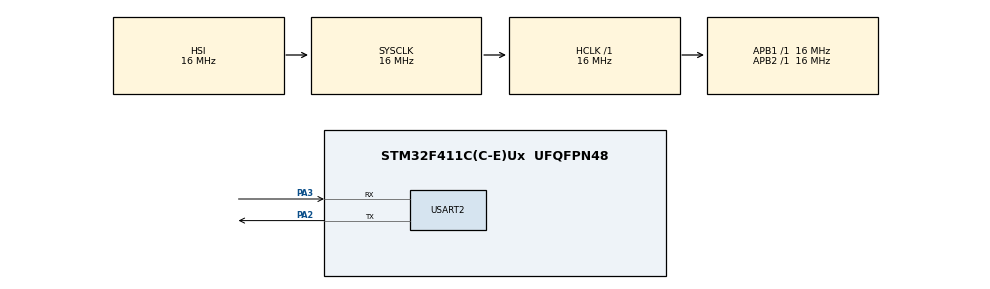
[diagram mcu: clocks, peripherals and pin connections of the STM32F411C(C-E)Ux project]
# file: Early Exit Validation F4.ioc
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Mcu.Family=STM32F4
Mcu.Name=STM32F411C(C-E)Ux
Mcu.Package=UFQFPN48
NVIC.PriorityGroup=NVIC_PRIORITYGROUP_4
PA13.Mode=Serial_Wire
PA13.Signal=SYS_JTMS-SWDIO
PA14.Mode=Serial_Wire
PA14.Signal=SYS_JTCK-SWCLK
PA2.Mode=Asynchronous
PA2.Signal=USART2_TX
PA3.Mode=Asynchronous
PA3.Signal=USART2_RX
ProjectManager.HeapSize=0x200
ProjectManager.StackSize=0x400
ProjectManager.TargetToolchain=STM32CubeIDE
RCC.AHBFreq_Value=16000000
RCC.APB1Freq_Value=16000000
RCC.APB2Freq_Value=16000000
RCC.CortexFreq_Value=16000000
RCC.HSE_VALUE=25000000
RCC.HSI_VALUE=16000000
RCC.LSE_VALUE=32768
RCC.SYSCLKFreq_VALUE=16000000
RCC.VCOOutputFreq_Value=192000000
STMicroelectronics.X-CUBE-AI.10.2.0.ActivationBufferSizeList=44732,44808,33208
STMicroelectronics.X-CUBE-AI.10.2.0.ActivationBuffers=pool0;pool0;pool0
STMicroelectronics.X-CUBE-AI.10.2.0.ActivationNames=pool0
STMicroelectronics.X-CUBE-AI.10.2.0.ActivationSizes=AI_NETWORK_1_DATA_ACTIVATION_1_SIZE
STMicroelectronics.X-CUBE-AI.10.2.0.ApplicationCcDeviceJjApplication=ApplicationTemplate
STMicroelectronics.X-CUBE-AI.10.2.0.HeapSize=0x800
STMicroelectronics.X-CUBE-AI.10.2.0.InternalRamActivationBufferMaxSize=AI_NETWORK_2_DATA_ACTIVATIONS_SIZE
STMicroelectronics.X-CUBE-AI.10.2.0.LatestDirectoryUsed-30e20236ca451895675bc07523db207a53c078bcb4689693956d8f04bd235fb7=D\:\\ARM Hackathon\\FINAL_HANDOFF
STMicroelectronics.X-CUBE-AI.10.2.0.LatestDirectoryUsed-bb43a51bcba1cfc3cbbd9259078b81ac906280b69a4e43d4efa3b40d29e1984f=D\:\\ARM Hackathon\\FINAL_HANDOFF
STMicroelectronics.X-CUBE-AI.10.2.0.LatestDirectoryUsed-d4300d666fe291a5c7089841f6ab343c647e5c0c7583c0506bb5bf4ecedfb07b=D\:\\ARM Hackathon\\FINAL_HANDOFF
STMicroelectronics.X-CUBE-AI.10.2.0.MaximumNumberOfInputLayer=1
STMicroelectronics.X-CUBE-AI.10.2.0.MaximumNumberOfOutputLayer=1
STMicroelectronics.X-CUBE-AI.10.2.0.MaximumSizeOfInputLayer=1
STMicroelectronics.X-CUBE-AI.10.2.0.MaximumSizeOfOutputLayer=1
STMicroelectronics.X-CUBE-AI.10.2.0.ModelActualCompression-30e20236ca451895675bc07523db207a53c078bcb4689693956d8f04bd235fb7=0.0
STMicroelectronics.X-CUBE-AI.10.2.0.ModelActualCompression-bb43a51bcba1cfc3cbbd9259078b81ac906280b69a4e43d4efa3b40d29e1984f=0.0
STMicroelectronics.X-CUBE-AI.10.2.0.ModelActualCompression-d4300d666fe291a5c7089841f6ab343c647e5c0c7583c0506bb5bf4ecedfb07b=0.0
STMicroelectronics.X-CUBE-AI.10.2.0.ModelCompression-30e20236ca451895675bc07523db207a53c078bcb4689693956d8f04bd235fb7=None
STMicroelectronics.X-CUBE-AI.10.2.0.ModelCompression-bb43a51bcba1cfc3cbbd9259078b81ac906280b69a4e43d4efa3b40d29e1984f=None
STMicroelectronics.X-CUBE-AI.10.2.0.ModelCompression-d4300d666fe291a5c7089841f6ab343c647e5c0c7583c0506bb5bf4ecedfb07b=None
STMicroelectronics.X-CUBE-AI.10.2.0.ModelFlashOccupation-30e20236ca451895675bc07523db207a53c078bcb4689693956d8f04bd235fb7=58004
STMicroelectronics.X-CUBE-AI.10.2.0.ModelFlashOccupation-bb43a51bcba1cfc3cbbd9259078b81ac906280b69a4e43d4efa3b40d29e1984f=60780
STMicroelectronics.X-CUBE-AI.10.2.0.ModelFlashOccupation-d4300d666fe291a5c7089841f6ab343c647e5c0c7583c0506bb5bf4ecedfb07b=12888
STMicroelectronics.X-CUBE-AI.10.2.0.ModelHashList=bb43a51bcba1cfc3cbbd9259078b81ac906280b69a4e43d4efa3b40d29e1984f;30e20236ca451895675bc07523db207a53c078bcb4689693956d8f04bd235fb7;d4300d666fe291a5c7089841f6ab343c647e5c0c7583c0506bb5bf4ecedfb07b
STMicroelectronics.X-CUBE-AI.10.2.0.ModelKind-30e20236ca451895675bc07523db207a53c078bcb4689693956d8f04bd235fb7=TFLITE
STMicroelectronics.X-CUBE-AI.10.2.0.ModelKind-bb43a51bcba1cfc3cbbd9259078b81ac906280b69a4e43d4efa3b40d29e1984f=TFLITE
STMicroelectronics.X-CUBE-AI.10.2.0.ModelKind-d4300d666fe291a5c7089841f6ab343c647e5c0c7583c0506bb5bf4ecedfb07b=TFLITE
STMicroelectronics.X-CUBE-AI.10.2.0.ModelMacc-30e20236ca451895675bc07523db207a53c078bcb4689693956d8f04bd235fb7=1209216
STMicroelectronics.X-CUBE-AI.10.2.0.ModelMacc-bb43a51bcba1cfc3cbbd9259078b81ac906280b69a4e43d4efa3b40d29e1984f=1528320
STMicroelectronics.X-CUBE-AI.10.2.0.ModelMacc-d4300d666fe291a5c7089841f6ab343c647e5c0c7583c0506bb5bf4ecedfb07b=8960
STMicroelectronics.X-CUBE-AI.10.2.0.ModelName-30e20236ca451895675bc07523db207a53c078bcb4689693956d8f04bd235fb7=network_2
STMicroelectronics.X-CUBE-AI.10.2.0.ModelName-bb43a51bcba1cfc3cbbd9259078b81ac906280b69a4e43d4efa3b40d29e1984f=network_1
STMicroelectronics.X-CUBE-AI.10.2.0.ModelName-d4300d666fe291a5c7089841f6ab343c647e5c0c7583c0506bb5bf4ecedfb07b=network_ee
STMicroelectronics.X-CUBE-AI.10.2.0.ModelNameList=network_1,network_2,network_ee
STMicroelectronics.X-CUBE-AI.10.2.0.ModelRamOccupation-30e20236ca451895675bc07523db207a53c078bcb4689693956d8f04bd235fb7=44808
STMicroelectronics.X-CUBE-AI.10.2.0.ModelRamOccupation-bb43a51bcba1cfc3cbbd9259078b81ac906280b69a4e43d4efa3b40d29e1984f=44732
STMicroelectronics.X-CUBE-AI.10.2.0.ModelRamOccupation-d4300d666fe291a5c7089841f6ab343c647e5c0c7583c0506bb5bf4ecedfb07b=33208
STMicroelectronics.X-CUBE-AI.10.2.0.ModelStructureFile-30e20236ca451895675bc07523db207a53c078bcb4689693956d8f04bd235fb7=D\:\\ARM Hackathon\\FINAL_HANDOFF\\network2.tflite
STMicroelectronics.X-CUBE-AI.10.2.0.ModelStructureFile-bb43a51bcba1cfc3cbbd9259078b81ac906280b69a4e43d4efa3b40d29e1984f=D\:\\ARM Hackathon\\FINAL_HANDOFF\\network1.tflite
STMicroelectronics.X-CUBE-AI.10.2.0.ModelStructureFile-d4300d666fe291a5c7089841f6ab343c647e5c0c7583c0506bb5bf4ecedfb07b=D\:\\ARM Hackathon\\FINAL_HANDOFF\\ee1.tflite
STMicroelectronics.X-CUBE-AI.10.2.0.ModelType-30e20236ca451895675bc07523db207a53c078bcb4689693956d8f04bd235fb7=STM32Cube.AI MCU runtime
STMicroelectronics.X-CUBE-AI.10.2.0.ModelType-bb43a51bcba1cfc3cbbd9259078b81ac906280b69a4e43d4efa3b40d29e1984f=STM32Cube.AI MCU runtime
STMicroelectronics.X-CUBE-AI.10.2.0.ModelType-d4300d666fe291a5c7089841f6ab343c647e5c0c7583c0506bb5bf4ecedfb07b=STM32Cube.AI MCU runtime
STMicroelectronics.X-CUBE-AI.10.2.0.ReadyForCodeGeneration=true
STMicroelectronics.X-CUBE-AI.10.2.0.StackSize=0x800
STMicroelectronics.X-CUBE-AI.10.2.0.WorkingBufferStartAddrList=0xFFFFFFFF,0xFFFFFFFF,0xFFFFFFFF
STMicroelectronics.X-CUBE-AI.10.2.0.XAaCUBEAaAICcArtificialOoIntelligenceJjCore=true
STMicroelectronics.X-CUBE-AI.10.2.0.copyWeightToRam=false
STMicroelectronics.X-CUBE-AI.10.2.0.customLayerConfigEnabled=false
STMicroelectronics.X-CUBE-AI.10.2.0.noOnnxIoTranspose=false
STMicroelectronics.X-CUBE-AI.10.2.0.useInputAllocation=true
STMicroelectronics.X-CUBE-AI.10.2.0.useOutputAllocation=true
USART2.VirtualMode=VM_ASYNC
VP_STMicroelectronics.X-CUBE-AI_VS_ArtificialOoIntelligenceJjXAaCUBEAaAI_10.2.0.Mode=ArtificialOoIntelligenceJjXAaCUBEAaAI
VP_STMicroelectronics.X-CUBE-AI_VS_DeviceJjApplication_10.2.0.Mode=DeviceJjApplication
board=custom

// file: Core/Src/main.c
/* USER CODE BEGIN Header */
/**
  ******************************************************************************
  * @file           : main.c
  * @brief          : Main program body
  ******************************************************************************
  * @attention
  *
  * Copyright (c) 2026 STMicroelectronics.
  * All rights reserved.
  *
  * This software is licensed under terms that can be found in the LICENSE file
  * in the root directory of this software component.
  * If no LICENSE file comes with this software, it is provided AS-IS.
  *
  ******************************************************************************
  */
/* USER CODE END Header */
#include "main.h"
#include "usart.h"
#include "gpio.h"
#include "app_x-cube-ai.h"

void SystemClock_Config(void);

/* USER CODE BEGIN 0 */
int __io_putchar(int ch)
{
    HAL_UART_Transmit(&huart2, (uint8_t *)&ch, 1, HAL_MAX_DELAY);
    return ch;
}
/* USER CODE END 0 */

int main(void)
{

  /* MCU Configuration--------------------------------------------------------*/

  /* Reset of all peripherals, Initializes the Flash interface and the Systick. */
  HAL_Init();

  /* Configure the system clock */
  SystemClock_Config();

  /* Initialize all configured peripherals */
  MX_GPIO_Init();
  MX_USART2_UART_Init();
  MX_X_CUBE_AI_Init();
  /* USER CODE BEGIN 2 */
  MX_X_CUBE_AI_Process();
  /* USER CODE END 2 */

  /* Infinite loop */
  while (1)
  {

  }
}

void SystemClock_Config(void)
{
  RCC_OscInitTypeDef RCC_OscInitStruct = {0};
  RCC_ClkInitTypeDef RCC_ClkInitStruct = {0};

  /** Configure the main internal regulator output voltage
  */
  __HAL_RCC_PWR_CLK_ENABLE();
  __HAL_PWR_VOLTAGESCALING_CONFIG(PWR_REGULATOR_VOLTAGE_SCALE1);

  /** Initializes the RCC Oscillators according to the specified parameters
  * in the RCC_OscInitTypeDef structure.
  */
  RCC_OscInitStruct.OscillatorType = RCC_OSCILLATORTYPE_HSI;
  RCC_OscInitStruct.HSIState = RCC_HSI_ON;
  RCC_OscInitStruct.HSICalibrationValue = RCC_HSICALIBRATION_DEFAULT;
  RCC_OscInitStruct.PLL.PLLState = RCC_PLL_NONE;
  if (HAL_RCC_OscConfig(&RCC_OscInitStruct) != HAL_OK)
  {
    Error_Handler();
  }

  /** Initializes the CPU, AHB and APB buses clocks
  */
  RCC_ClkInitStruct.ClockType = RCC_CLOCKTYPE_HCLK|RCC_CLOCKTYPE_SYSCLK
                              |RCC_CLOCKTYPE_PCLK1|RCC_CLOCKTYPE_PCLK2;
  RCC_ClkInitStruct.SYSCLKSource = RCC_SYSCLKSOURCE_HSI;
  RCC_ClkInitStruct.AHBCLKDivider = RCC_SYSCLK_DIV1;
  RCC_ClkInitStruct.APB1CLKDivider = RCC_HCLK_DIV1;
  RCC_ClkInitStruct.APB2CLKDivider = RCC_HCLK_DIV1;

  if (HAL_RCC_ClockConfig(&RCC_ClkInitStruct, FLASH_LATENCY_0) != HAL_OK)
  {
    Error_Handler();
  }
}

void Error_Handler(void)
{
  __disable_irq();
  while (1)
  {
  }
}
